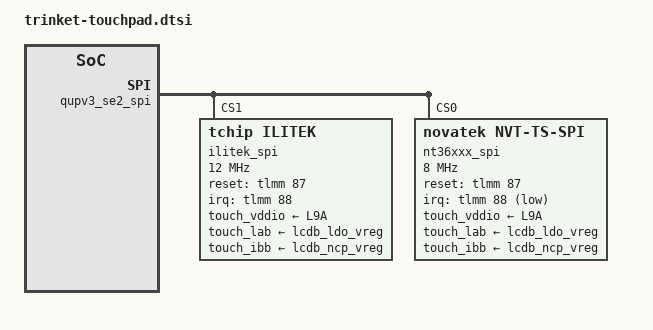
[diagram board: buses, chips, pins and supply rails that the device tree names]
/*
 * Copyright (C) 2010 - 2018 Novatek, Inc.
 *
 * $Revision$
 * $Date$
 *
 * This program is free software; you can redistribute it and/or modify
 * it under the terms of the GNU General Public License as published by
 * the Free Software Foundation; either version 2 of the License, or
 * (at your option) any later version.
 *
 * This program is distributed in the hope that it will be useful, but WITHOUT
 * ANY WARRANTY; without even the implied warranty of MERCHANTABILITY or
 * FITNESS FOR A PARTICULAR PURPOSE.  See the GNU General Public License for
 * more details.
 *
 */

&qupv3_se2_spi {

	status = "ok";
	ilitek_spi{
		status = "ok";
		compatible = "tchip,ilitek";
		reg = <1>; //change it in driver for multi spi touchscreen

		poll_mode = <0>;
		spi-max-frequency = <12000000>;

		/* regulator Configuration */
		touch_vddio-supply = <&L9A>;
		touch_lab-supply = <&lcdb_ldo_vreg>;
		touch_ibb-supply = <&lcdb_ncp_vreg>;

		touch,reset-gpio = <&tlmm 87 0x00>;
		touch,irq-gpio = <&tlmm 88 0x2002>;
	};

	nt36xxx_spi{
		status = "ok";
		compatible = "novatek,NVT-ts-spi";
		reg = <0>; //Same as CS ID

		/* SPI Configuration */
		spi-cs-high;
		spi-max-frequency = <8000000>;	//4800000,5000000,8000000,9600000,15000000,19200000

		/* regulator Configuration */
		touch_vddio-supply = <&L9A>;
		touch_lab-supply = <&lcdb_ldo_vreg>;
		touch_ibb-supply = <&lcdb_ncp_vreg>;

		/* Novatek GPIO Configuration */
		novatek,reset-gpio = <&tlmm 87 0x00>;
		novatek,irq-gpio = <&tlmm 88 0x2001>;

		/* 525 */
		//novatek,swrst-n8-addr = <0x01F01A>;

		/* 672A, 525B, 675, 526 */
		novatek,swrst-n8-addr = <0x03F0FE>;
		novatek,spi-rd-fast-addr = <0x03F310>;

		/* MP */
		novatek,mp-support-dt;

		novatek-mp-criteria-5108@0 {
			#address-cells = <1>;
			#size-cells = <0>;
			compatible = "novatek-mp-criteria-5108";

			/* MP Config */
			IC_X_CFG_SIZE = <15>;
			IC_Y_CFG_SIZE = <35>;
			IC_KEY_CFG_SIZE = <4>;
			X_Channel = <15>;
			Y_Channel = <35>;
			AIN_X = <0 1 2 3 4 5 6 7 8 9 10 11 12 13 14>;
			AIN_Y = <0 1 2 3 4 5 6 7 8 9 10 11 12 13 14 15 16 17
						18 19 20 21 22 23 24 25 26 27 28 29 30 31 32 33 34>;
			/*AIN_KEY = <0 1 2 0xFF 0xFF 0xFF 0xFF 0xFF>;*/

			/* MP Criteria */
			PS_Config_Lmt_Short_Rawdata_P = <
			    14008 14008 14008 14008 14008 14008 14008 14008 14008 14008 14008 14008 14008 14008 14008
			    14008 14008 14008 14008 14008 14008 14008 14008 14008 14008 14008 14008 14008 14008 14008
			    14008 14008 14008 14008 14008 14008 14008 14008 14008 14008 14008 14008 14008 14008 14008
			    14008 14008 14008 14008 14008 14008 14008 14008 14008 14008 14008 14008 14008 14008 14008
			    14008 14008 14008 14008 14008 14008 14008 14008 14008 14008 14008 14008 14008 14008 14008
			    14008 14008 14008 14008 14008 14008 14008 14008 14008 14008 14008 14008 14008 14008 14008
			    14008 14008 14008 14008 14008 14008 14008 14008 14008 14008 14008 14008 14008 14008 14008
			    14008 14008 14008 14008 14008 14008 14008 14008 14008 14008 14008 14008 14008 14008 14008
			    14008 14008 14008 14008 14008 14008 14008 14008 14008 14008 14008 14008 14008 14008 14008
			    14008 14008 14008 14008 14008 14008 14008 14008 14008 14008 14008 14008 14008 14008 14008
			    14008 14008 14008 14008 14008 14008 14008 14008 14008 14008 14008 14008 14008 14008 14008
			    14008 14008 14008 14008 14008 14008 14008 14008 14008 14008 14008 14008 14008 14008 14008
			    14008 14008 14008 14008 14008 14008 14008 14008 14008 14008 14008 14008 14008 14008 14008
			    14008 14008 14008 14008 14008 14008 14008 14008 14008 14008 14008 14008 14008 14008 14008
			    14008 14008 14008 14008 14008 14008 14008 14008 14008 14008 14008 14008 14008 14008 14008
			    14008 14008 14008 14008 14008 14008 14008 14008 14008 14008 14008 14008 14008 14008 14008
			    14008 14008 14008 14008 14008 14008 14008 14008 14008 14008 14008 14008 14008 14008 14008
			    14008 14008 14008 14008 14008 14008 14008 14008 14008 14008 14008 14008 14008 14008 14008
			    14008 14008 14008 14008 14008 14008 14008 14008 14008 14008 14008 14008 14008 14008 14008
			    14008 14008 14008 14008 14008 14008 14008 14008 14008 14008 14008 14008 14008 14008 14008
			    14008 14008 14008 14008 14008 14008 14008 14008 14008 14008 14008 14008 14008 14008 14008
			    14008 14008 14008 14008 14008 14008 14008 14008 14008 14008 14008 14008 14008 14008 14008
			    14008 14008 14008 14008 14008 14008 14008 14008 14008 14008 14008 14008 14008 14008 14008
			    14008 14008 14008 14008 14008 14008 14008 14008 14008 14008 14008 14008 14008 14008 14008
			    14008 14008 14008 14008 14008 14008 14008 14008 14008 14008 14008 14008 14008 14008 14008
			    14008 14008 14008 14008 14008 14008 14008 14008 14008 14008 14008 14008 14008 14008 14008
			    14008 14008 14008 14008 14008 14008 14008 14008 14008 14008 14008 14008 14008 14008 14008
			    14008 14008 14008 14008 14008 14008 14008 14008 14008 14008 14008 14008 14008 14008 14008
			    14008 14008 14008 14008 14008 14008 14008 14008 14008 14008 14008 14008 14008 14008 14008
			    14008 14008 14008 14008 14008 14008 14008 14008 14008 14008 14008 14008 14008 14008 14008
			    14008 14008 14008 14008 14008 14008 14008 14008 14008 14008 14008 14008 14008 14008 14008
			    14008 14008 14008 14008 14008 14008 14008 14008 14008 14008 14008 14008 14008 14008 14008
			    14008 14008 14008 14008 14008 14008 14008 14008 14008 14008 14008 14008 14008 14008 14008
			    14008 14008 14008 14008 14008 14008 14008 14008 14008 14008 14008 14008 14008 14008 14008
			    14008 14008 14008 14008 14008 14008 14008 14008 14008 14008 14008 14008 14008 14008 14008
			    >;

			   PS_Config_Lmt_Short_Rawdata_N = <
			    10100 10100 10100 10100 10100 10100 10100 10100 10100 10100 10100 10100 10100 10100 10100
			    10100 10100 10100 10100 10100 10100 10100 10100 10100 10100 10100 10100 10100 10100 10100
			    10100 10100 10100 10100 10100 10100 10100 10100 10100 10100 10100 10100 10100 10100 10100
			    10100 10100 10100 10100 10100 10100 10100 10100 10100 10100 10100 10100 10100 10100 10100
			    10100 10100 10100 10100 10100 10100 10100 10100 10100 10100 10100 10100 10100 10100 10100
			    10100 10100 10100 10100 10100 10100 10100 10100 10100 10100 10100 10100 10100 10100 10100
			    10100 10100 10100 10100 10100 10100 10100 10100 10100 10100 10100 10100 10100 10100 10100
			    10100 10100 10100 10100 10100 10100 10100 10100 10100 10100 10100 10100 10100 10100 10100
			    10100 10100 10100 10100 10100 10100 10100 10100 10100 10100 10100 10100 10100 10100 10100
			    10100 10100 10100 10100 10100 10100 10100 10100 10100 10100 10100 10100 10100 10100 10100
			    10100 10100 10100 10100 10100 10100 10100 10100 10100 10100 10100 10100 10100 10100 10100
			    10100 10100 10100 10100 10100 10100 10100 10100 10100 10100 10100 10100 10100 10100 10100
			    10100 10100 10100 10100 10100 10100 10100 10100 10100 10100 10100 10100 10100 10100 10100
			    10100 10100 10100 10100 10100 10100 10100 10100 10100 10100 10100 10100 10100 10100 10100
			    10100 10100 10100 10100 10100 10100 10100 10100 10100 10100 10100 10100 10100 10100 10100
			    10100 10100 10100 10100 10100 10100 10100 10100 10100 10100 10100 10100 10100 10100 10100
			    10100 10100 10100 10100 10100 10100 10100 10100 10100 10100 10100 10100 10100 10100 10100
			    10100 10100 10100 10100 10100 10100 10100 10100 10100 10100 10100 10100 10100 10100 10100
			    10100 10100 10100 10100 10100 10100 10100 10100 10100 10100 10100 10100 10100 10100 10100
			    10100 10100 10100 10100 10100 10100 10100 10100 10100 10100 10100 10100 10100 10100 10100
			    10100 10100 10100 10100 10100 10100 10100 10100 10100 10100 10100 10100 10100 10100 10100
			    10100 10100 10100 10100 10100 10100 10100 10100 10100 10100 10100 10100 10100 10100 10100
			    10100 10100 10100 10100 10100 10100 10100 10100 10100 10100 10100 10100 10100 10100 10100
			    10100 10100 10100 10100 10100 10100 10100 10100 10100 10100 10100 10100 10100 10100 10100
			    10100 10100 10100 10100 10100 10100 10100 10100 10100 10100 10100 10100 10100 10100 10100
			    10100 10100 10100 10100 10100 10100 10100 10100 10100 10100 10100 10100 10100 10100 10100
			    10100 10100 10100 10100 10100 10100 10100 10100 10100 10100 10100 10100 10100 10100 10100
			    10100 10100 10100 10100 10100 10100 10100 10100 10100 10100 10100 10100 10100 10100 10100
			    10100 10100 10100 10100 10100 10100 10100 10100 10100 10100 10100 10100 10100 10100 10100
			    10100 10100 10100 10100 10100 10100 10100 10100 10100 10100 10100 10100 10100 10100 10100
			    10100 10100 10100 10100 10100 10100 10100 10100 10100 10100 10100 10100 10100 10100 10100
			    10100 10100 10100 10100 10100 10100 10100 10100 10100 10100 10100 10100 10100 10100 10100
			    10100 10100 10100 10100 10100 10100 10100 10100 10100 10100 10100 10100 10100 10100 10100
			    10100 10100 10100 10100 10100 10100 10100 10100 10100 10100 10100 10100 10100 10100 10100
			    10100 10100 10100 10100 10100 10100 10100 10100 10100 10100 10100 10100 10100 10100 10100
			    >;

			   PS_Config_Lmt_Open_Rawdata_P = <
			    2052 2185 2263 2352 2391 2505 65535 65535 2594 2446 2414 2335 2249 2167 65535
			    2103 2200 2263 2342 2352 2344 2283 2574 2437 2442 2423 2388 2316 2236 2433
			    2118 2216 2272 2347 2355 2331 2316 2557 2401 2388 2374 2351 2288 2221 2413
			    2188 2280 2345 2414 2427 2414 2400 2607 2475 2460 2445 2424 2358 2288 2478
			    2233 2325 2386 2456 2460 2452 2436 2651 2515 2507 2501 2485 2423 2351 2518
			    2253 2335 2394 2462 2458 2453 2446 2628 2495 2486 2481 2473 2409 2332 2492
			    2043 2141 2197 2282 2340 2327 2319 2623 2394 2376 2357 2283 2208 2149 2380
			    2077 2183 2236 2327 2378 2367 2355 2659 2450 2426 2410 2332 2268 2200 2420
			    2095 2185 2236 2324 2364 2354 2337 2681 2471 2446 2433 2358 2291 2216 2423
			    2171 2273 2334 2423 2462 2456 2433 2740 2545 2518 2504 2427 2364 2288 2496
			    2224 2324 2378 2465 2495 2491 2473 2717 2545 2522 2512 2450 2381 2309 2492
			    2193 2288 2340 2420 2440 2430 2407 2700 2524 2502 2489 2439 2374 2304 2466
			    2772 2868 2928 2916 2913 2908 2905 2796 3015 3008 2998 2999 3013 2952 3060
			    2885 2977 3035 3022 3013 2999 2989 2792 3104 3097 3090 3090 3104 3047 3142
			    2851 2936 2979 2964 2957 2962 2946 2800 3074 3064 3052 3060 3081 3032 3124
			    2944 3041 3088 3070 3070 3077 3062 2875 3204 3196 3189 3182 3196 3147 3238
			    2996 3085 3129 3108 3108 3121 3108 2944 3258 3250 3242 3248 3260 3229 3306
			    2872 2952 2988 2959 2963 2969 2969 2831 3221 3232 3221 3229 3245 3218 3278
			    3042 3119 3155 3127 3127 3130 3132 2967 3329 3332 3330 3333 3348 3333 3407
			    3149 3237 3261 3229 3232 3240 3232 3057 3396 3398 3396 3395 3409 3405 3460
			    3119 3196 3209 3182 3192 3208 3208 3067 3323 3333 3337 3337 3358 3363 3424
			    3214 3288 3306 3280 3288 3309 3310 3180 3427 3431 3445 3438 3450 3460 3515
			    3368 3435 3435 3411 3414 3435 3435 3216 3528 3539 3542 3546 3562 3572 3628
			    3324 3378 3385 3360 3373 3392 3396 3202 3496 3503 3509 3522 3530 3546 3594
			    3430 3477 3481 3453 3466 3476 3487 3255 3610 3621 3624 3641 3647 3667 3731
			    3434 3467 3481 3448 3456 3461 3463 3350 3631 3640 3653 3664 3670 3696 3768
			    3542 3558 3561 3538 3538 3549 3546 3316 3648 3663 3664 3676 3684 3705 3774
			    3623 3633 3637 3612 3617 3633 3644 3417 3782 3797 3800 3810 3817 3837 3919
			    3738 3742 3732 3705 3705 3718 3718 3536 3831 3852 3853 3867 3873 3889 3984
			    3039 3119 3185 3235 3222 3222 3198 3520 3360 3356 3352 3346 3290 3206 3291
			    3120 3208 3280 3330 3314 3320 3314 3548 3402 3394 3389 3386 3343 3263 3333
			    2846 3096 3146 3198 3178 3173 3160 3445 3294 3290 3290 3296 3267 3206 3084
			    2970 3235 3283 3317 3290 3293 3286 3568 3421 3425 3415 3427 3396 3326 3198
			    3044 3378 3434 3463 3443 3450 3443 3699 3558 3564 3565 3568 3542 3473 3268
			    3034 3391 3467 3483 3464 3463 3463 3725 3585 3585 3574 3584 3571 3490 3204
			    >;

			   PS_Config_Lmt_Open_Rawdata_N = <
			    798 850 880 915 930 974 (-65535) (-65535) 1009 951 939 908 874 842 (-65535)
			    818 855 880 911 915 911 888 1001 948 949 942 929 901 869 946
			    823 861 883 912 916 906 901 994 934 929 923 914 889 864 938
			    851 887 912 939 944 939 933 1014 962 957 950 943 917 889 963
			    868 904 927 955 957 953 947 1030 978 974 972 966 942 914 979
			    876 908 931 957 955 954 951 1022 970 967 964 962 936 907 969
			    794 832 854 887 910 904 902 1020 931 924 916 888 859 836 925
			    808 848 869 904 925 920 916 1034 953 943 937 907 882 855 941
			    814 850 869 903 919 915 908 1042 960 951 946 917 890 861 942
			    844 884 907 942 957 955 946 1065 990 979 973 944 919 889 971
			    865 903 925 958 970 968 962 1056 990 981 977 953 926 898 969
			    852 889 910 941 949 945 936 1050 981 973 968 948 923 896 959
			    1078 1115 1139 1134 1132 1131 1130 1087 1172 1169 1165 1166 1172 1148 1190
			    1122 1158 1180 1175 1172 1166 1162 1085 1207 1204 1201 1201 1207 1184 1221
			    1108 1141 1158 1153 1150 1151 1145 1089 1195 1191 1187 1190 1198 1179 1215
			    1145 1182 1201 1193 1193 1196 1191 1118 1246 1243 1240 1237 1243 1224 1259
			    1165 1200 1216 1209 1209 1214 1209 1145 1267 1263 1261 1263 1267 1256 1285
			    1117 1148 1162 1150 1152 1154 1154 1100 1252 1257 1252 1256 1262 1251 1275
			    1183 1212 1226 1216 1216 1217 1218 1154 1294 1295 1295 1296 1302 1296 1324
			    1224 1258 1268 1256 1257 1260 1257 1188 1321 1321 1321 1320 1326 1324 1345
			    1212 1243 1248 1237 1241 1247 1247 1192 1292 1296 1298 1298 1305 1308 1331
			    1249 1279 1285 1275 1279 1286 1287 1237 1332 1334 1340 1337 1341 1345 1366
			    1309 1336 1336 1326 1327 1336 1336 1251 1372 1376 1377 1379 1385 1389 1411
			    1293 1313 1316 1307 1312 1319 1321 1245 1359 1362 1364 1369 1373 1379 1397
			    1333 1352 1354 1342 1347 1351 1356 1266 1403 1408 1409 1416 1418 1426 1450
			    1335 1348 1354 1341 1344 1346 1346 1303 1412 1415 1420 1425 1427 1437 1465
			    1377 1383 1384 1375 1375 1380 1379 1289 1419 1424 1425 1429 1433 1440 1467
			    1408 1412 1414 1405 1406 1412 1417 1328 1471 1476 1477 1481 1484 1492 1524
			    1453 1455 1451 1440 1440 1445 1445 1375 1490 1498 1498 1504 1506 1512 1549
			    1182 1212 1238 1258 1253 1253 1243 1369 1307 1305 1303 1301 1279 1247 1280
			    1213 1247 1275 1295 1289 1291 1289 1379 1323 1319 1318 1317 1300 1268 1296
			    1107 1204 1223 1243 1235 1234 1229 1340 1281 1279 1279 1281 1270 1247 1199
			    1155 1258 1276 1290 1279 1280 1277 1387 1330 1332 1328 1332 1321 1293 1243
			    1183 1313 1335 1346 1338 1341 1338 1438 1383 1386 1386 1387 1377 1350 1271
			    1179 1318 1348 1354 1347 1346 1346 1448 1394 1394 1389 1393 1388 1357 1246
			    >;

			   PS_Config_Lmt_FW_Rawdata_P = <
			    1097 1117 1134 1138 1155 1143 65535 65535 1103 1136 1124 1104 1136 1111 65535
			    1134 1142 1110 1103 1129 1129 1108 1118 1153 1138 1129 1115 1131 1114 1118
			    1110 1107 1146 1129 1143 1108 1120 1125 1125 1115 1115 1138 1127 1107 1146
			    1131 1110 1155 1094 1104 1125 1149 1141 1124 1108 1125 1149 1141 1125 1138
			    1101 1097 1107 1110 1150 1163 1086 1096 1139 1142 1134 1089 1132 1129 1121
			    1131 1138 1166 1097 1120 1141 1113 1145 1117 1121 1145 1118 1139 1136 1139
			    1072 1097 1117 1155 1127 1118 1129 1141 1108 1120 1141 1141 1134 1124 1129
			    1099 1125 1079 1155 1079 1110 1163 1142 1085 1118 1164 1153 1125 1110 1164
			    1076 1163 1100 1127 1132 1090 1121 1159 1094 1129 1125 1114 1139 1113 1113
			    1108 1100 1149 1099 1118 1145 1131 1107 1152 1132 1093 1090 1160 1149 1125
			    1118 1118 1148 1082 1153 1152 1110 1124 1117 1113 1129 1120 1115 1121 1093
			    1111 1114 1132 1139 1120 1125 1108 1120 1104 1138 1092 1125 1148 1125 1153
			    1114 1096 1131 1157 1111 1106 1121 1138 1145 1177 1096 1065 1104 1089 1127
			    1114 1106 1121 1139 1134 1117 1110 1173 1111 1117 1125 1118 1128 1114 1090
			    1134 1148 1101 1076 1117 1157 1176 1121 1124 1146 1134 1082 1104 1086 1115
			    1086 1122 1110 1127 1138 1124 1087 1136 1090 1120 1135 1159 1169 1157 1086
			    1097 1135 1092 1128 1157 1115 1083 1111 1132 1136 1118 1110 1099 1093 1103
			    1082 1142 1100 1106 1127 1148 1106 1125 1142 1155 1169 1082 1082 1079 1093
			    1087 1120 1083 1120 1153 1111 1092 1124 1124 1087 1097 1107 1136 1149 1174
			    1132 1075 1103 1141 1145 1111 1103 1131 1076 1104 1114 1128 1135 1103 1131
			    1128 1075 1097 1135 1162 1125 1090 1111 1113 1143 1160 1162 1104 1075 1086
			    1120 1117 1094 1142 1134 1120 1145 1122 1099 1107 1111 1121 1142 1122 1150
			    1107 1150 1094 1113 1146 1110 1117 1135 1115 1122 1100 1124 1124 1150 1169
			    1101 1111 1121 1087 1113 1128 1127 1121 1115 1118 1135 1132 1145 1099 1132
			    1108 1153 1115 1103 1122 1139 1149 1155 1125 1087 1082 1113 1143 1122 1124
			    1148 1093 1125 1171 1174 1064 1065 1096 1101 1113 1120 1152 1157 1107 1111
			    1076 1138 1155 1155 1065 1080 1108 1127 1188 1073 1061 1086 1101 1120 1176
			    1117 1120 1138 1099 1120 1145 1124 1097 1143 1157 1089 1078 1085 1101 1072
			    1089 1096 1124 1174 1150 1107 1090 1180 1148 1145 1152 1139 1118 1080 1110
			    1120 1111 1141 1111 1141 1146 1104 1104 1162 1148 1120 1103 1159 1090 1107
			    1086 1115 1127 1113 1120 1141 1114 1138 1061 1057 1061 1068 1185 1136 1136
			    1110 1100 1148 1114 1111 1120 1124 1118 1113 1106 1128 1131 1121 1110 1134
			    1107 1143 1087 1120 1132 1166 1171 1148 1079 1085 1072 1097 1076 1177 1078
			    1160 1096 1166 1065 1107 1132 1143 1128 1104 1118 1096 1101 1090 1152 1136
			    1092 1160 1114 1120 1163 1100 1089 1110 1115 1108 1120 1120 1114 1124 1131
			    >;

			   PS_Config_Lmt_FW_Rawdata_N = <
			    470 478 486 487 495 490 (-65535) (-65535) 472 487 481 473 487 476 (-65535)
			    486 489 475 472 484 484 475 479 494 487 484 478 484 477 479
			    475 474 491 484 490 475 480 482 482 478 478 487 483 474 491
			    484 475 495 469 473 482 492 489 481 475 482 492 489 482 487
			    472 470 474 475 493 498 465 469 488 489 486 466 485 484 480
			    484 487 499 470 480 489 477 490 478 480 490 479 488 487 488
			    459 470 478 495 483 479 484 489 475 480 489 489 486 481 484
			    471 482 462 495 462 475 498 489 465 479 499 494 482 475 499
			    461 498 471 483 485 467 480 496 469 484 482 477 488 477 477
			    475 471 492 471 479 490 484 474 493 485 468 467 497 492 482
			    479 479 492 463 494 493 475 481 478 477 484 480 478 480 468
			    476 477 485 488 480 482 475 480 473 487 468 482 492 482 494
			    477 469 484 496 476 474 480 487 490 504 469 456 473 466 483
			    477 474 480 488 486 478 475 502 476 478 482 479 483 477 467
			    486 492 472 461 478 496 504 480 481 491 486 463 473 465 478
			    465 481 475 483 487 481 466 487 467 480 486 496 501 496 465
			    470 486 468 483 496 478 464 476 485 487 479 475 471 468 472
			    463 489 471 474 483 492 474 482 489 495 501 463 463 462 468
			    466 480 464 480 494 476 468 481 481 466 470 474 487 492 503
			    485 460 472 489 490 476 472 484 461 473 477 483 486 472 484
			    483 460 470 486 498 482 467 476 477 490 497 498 473 460 465
			    480 478 469 489 486 480 490 481 471 474 476 480 489 481 493
			    474 493 469 477 491 475 478 486 478 481 471 481 481 493 501
			    472 476 480 466 477 483 483 480 478 479 486 485 490 471 485
			    475 494 478 472 481 488 492 495 482 466 463 477 490 481 481
			    492 468 482 502 503 456 456 469 472 477 480 493 496 474 476
			    461 487 495 495 456 463 475 483 509 460 454 465 472 480 504
			    478 480 487 471 480 490 481 470 490 496 466 462 465 472 459
			    466 469 481 503 493 474 467 505 492 490 493 488 479 463 475
			    480 476 489 476 489 491 473 473 498 492 480 472 496 467 474
			    465 478 483 477 480 489 477 487 454 453 454 457 508 487 487
			    475 471 492 477 476 480 481 479 477 474 483 484 480 475 486
			    474 490 466 480 485 499 502 492 462 465 459 470 461 504 462
			    497 469 499 456 474 485 490 483 473 479 469 472 467 493 487
			    468 497 477 480 498 471 466 475 478 475 480 480 477 481 484
			    >;

			   PS_Config_Lmt_FW_CC_P = <
			    42 44 45 45 46 46 65535 65535 42 44 44 44 44 42 65535
			    41 41 42 42 44 44 44 40 44 44 44 44 44 44 44
			    42 42 44 45 45 45 45 40 42 42 44 44 44 44 44
			    44 44 45 45 45 46 46 40 42 44 44 44 44 44 44
			    42 42 44 44 44 45 45 40 42 44 44 44 44 44 44
			    44 44 44 45 45 45 46 40 42 44 44 44 44 44 44
			    42 42 44 44 45 45 45 41 44 44 45 45 44 44 45
			    44 44 44 45 45 46 46 41 45 45 45 45 45 45 45
			    42 42 42 44 44 45 45 41 44 44 45 45 44 44 45
			    42 44 44 45 45 45 46 41 44 44 44 44 44 44 44
			    42 42 44 44 45 45 45 41 44 44 44 44 44 44 44
			    42 42 44 45 45 45 45 41 45 45 45 45 45 45 45
			    48 48 48 49 49 49 49 49 45 45 46 46 46 46 46
			    49 49 49 49 49 51 51 49 46 46 48 48 48 48 48
			    49 48 49 49 49 49 51 48 46 46 46 46 46 46 48
			    49 49 49 49 51 51 51 49 46 46 46 46 48 48 48
			    49 49 49 49 49 51 51 48 46 46 46 48 48 48 48
			    51 49 49 51 51 51 51 48 48 48 48 49 49 49 49
			    49 48 49 49 49 49 51 48 46 46 46 48 48 48 48
			    51 49 51 51 51 51 52 48 48 48 48 48 48 49 49
			    49 49 49 49 49 49 51 49 46 46 48 48 48 48 48
			    49 49 49 49 49 51 51 49 48 48 48 48 48 49 49
			    49 49 49 49 49 51 51 48 46 46 48 48 48 48 48
			    52 51 52 52 52 52 52 49 48 48 48 48 48 49 49
			    51 49 51 51 51 51 51 49 48 48 48 48 48 49 49
			    52 51 51 51 51 52 52 51 48 48 48 48 48 49 49
			    52 51 51 51 52 52 52 49 48 49 49 49 49 49 49
			    52 51 51 51 51 51 52 51 48 48 49 49 49 49 51
			    51 51 51 51 51 51 51 49 48 48 48 48 48 48 49
			    45 45 45 46 46 46 48 44 46 46 46 46 45 45 45
			    46 46 46 48 48 48 48 45 48 48 48 48 46 46 46
			    46 46 46 48 48 48 48 45 48 48 48 48 46 46 46
			    48 46 48 48 48 48 48 45 48 48 48 48 48 46 48
			    46 46 46 48 48 48 48 45 46 46 48 48 48 46 48
			    49 46 48 48 48 49 49 46 48 48 48 48 48 48 49
			    >;

			   PS_Config_Lmt_FW_CC_N = <
			    19 19 20 20 21 21 (-65535) (-65535) 19 19 19 19 19 19 (-65535)
			    18 18 19 19 19 19 19 17 19 19 19 19 19 19 19
			    19 19 19 20 20 20 20 17 19 19 19 19 19 19 19
			    19 19 20 20 20 21 21 17 19 19 19 19 19 19 19
			    19 19 19 19 19 20 20 17 19 19 19 19 19 19 19
			    19 19 19 20 20 20 21 17 19 19 19 19 19 19 19
			    19 19 19 19 20 20 20 18 19 19 20 20 19 19 20
			    19 19 19 20 20 21 21 18 20 20 20 20 20 20 20
			    19 19 19 19 19 20 20 18 19 19 20 20 19 19 20
			    19 19 19 20 20 20 21 18 19 19 19 19 19 19 19
			    19 19 19 19 20 20 20 18 19 19 19 19 19 19 19
			    19 19 19 20 20 20 20 18 20 20 20 20 20 20 20
			    21 21 21 22 22 22 22 22 20 20 21 21 21 21 21
			    22 22 22 22 22 22 22 22 21 21 21 21 21 21 21
			    22 21 22 22 22 22 22 21 21 21 21 21 21 21 21
			    22 22 22 22 22 22 22 22 21 21 21 21 21 21 21
			    22 22 22 22 22 22 22 21 21 21 21 21 21 21 21
			    22 22 22 22 22 22 22 21 21 21 21 22 22 22 22
			    22 21 22 22 22 22 22 21 21 21 21 21 21 21 21
			    22 22 22 22 22 22 23 21 21 21 21 21 21 22 22
			    22 22 22 22 22 22 22 22 21 21 21 21 21 21 21
			    22 22 22 22 22 22 22 22 21 21 21 21 21 22 22
			    22 22 22 22 22 22 22 21 21 21 21 21 21 21 21
			    23 22 23 23 23 23 23 22 21 21 21 21 21 22 22
			    22 22 22 22 22 22 22 22 21 21 21 21 21 22 22
			    23 22 22 22 22 23 23 22 21 21 21 21 21 22 22
			    23 22 22 22 23 23 23 22 21 22 22 22 22 22 22
			    23 22 22 22 22 22 23 22 21 21 22 22 22 22 22
			    22 22 22 22 22 22 22 22 21 21 21 21 21 21 22
			    20 20 20 21 21 21 21 19 21 21 21 21 20 20 20
			    21 21 21 21 21 21 21 20 21 21 21 21 21 21 21
			    21 21 21 21 21 21 21 20 21 21 21 21 21 21 21
			    21 21 21 21 21 21 21 20 21 21 21 21 21 21 21
			    21 21 21 21 21 21 21 20 21 21 21 21 21 21 21
			    22 21 21 21 21 22 22 21 21 21 21 21 21 21 22
			    >;

			   PS_Config_Lmt_FW_Diff_P = <
			    50 50 50 50 50 50 65535 65535 50 50 50 50 50 50 65535
			    50 50 50 50 50 50 50 50 50 50 50 50 50 50 50
			    50 50 50 50 50 50 50 50 50 50 50 50 50 50 50
			    50 50 50 50 50 50 50 50 50 50 50 50 50 50 50
			    50 50 50 50 50 50 50 50 50 50 50 50 50 50 50
			    50 50 50 50 50 50 50 50 50 50 50 50 50 50 50
			    50 50 50 50 50 50 50 50 50 50 50 50 50 50 50
			    50 50 50 50 50 50 50 50 50 50 50 50 50 50 50
			    50 50 50 50 50 50 50 50 50 50 50 50 50 50 50
			    50 50 50 50 50 50 50 50 50 50 50 50 50 50 50
			    50 50 50 50 50 50 50 50 50 50 50 50 50 50 50
			    50 50 50 50 50 50 50 50 50 50 50 50 50 50 50
			    50 50 50 50 50 50 50 50 50 50 50 50 50 50 50
			    50 50 50 50 50 50 50 50 50 50 50 50 50 50 50
			    50 50 50 50 50 50 50 50 50 50 50 50 50 50 50
			    50 50 50 50 50 50 50 50 50 50 50 50 50 50 50
			    50 50 50 50 50 50 50 50 50 50 50 50 50 50 50
			    50 50 50 50 50 50 50 50 50 50 50 50 50 50 50
			    50 50 50 50 50 50 50 50 50 50 50 50 50 50 50
			    50 50 50 50 50 50 50 50 50 50 50 50 50 50 50
			    50 50 50 50 50 50 50 50 50 50 50 50 50 50 50
			    50 50 50 50 50 50 50 50 50 50 50 50 50 50 50
			    50 50 50 50 50 50 50 50 50 50 50 50 50 50 50
			    50 50 50 50 50 50 50 50 50 50 50 50 50 50 50
			    50 50 50 50 50 50 50 50 50 50 50 50 50 50 50
			    50 50 50 50 50 50 50 50 50 50 50 50 50 50 50
			    50 50 50 50 50 50 50 50 50 50 50 50 50 50 50
			    50 50 50 50 50 50 50 50 50 50 50 50 50 50 50
			    50 50 50 50 50 50 50 50 50 50 50 50 50 50 50
			    50 50 50 50 50 50 50 50 50 50 50 50 50 50 50
			    50 50 50 50 50 50 50 50 50 50 50 50 50 50 50
			    50 50 50 50 50 50 50 50 50 50 50 50 50 50 50
			    50 50 50 50 50 50 50 50 50 50 50 50 50 50 50
			    50 50 50 50 50 50 50 50 50 50 50 50 50 50 50
			    50 50 50 50 50 50 50 50 50 50 50 50 50 50 50
			    >;

			   PS_Config_Lmt_FW_Diff_N = <
			    (-50) (-50) (-50) (-50) (-50) (-50) (-65535) (-65535) (-50) (-50) (-50) (-50) (-50) (-50) (-65535)
			    (-50) (-50) (-50) (-50) (-50) (-50) (-50) (-50) (-50) (-50) (-50) (-50) (-50) (-50) (-50)
			    (-50) (-50) (-50) (-50) (-50) (-50) (-50) (-50) (-50) (-50) (-50) (-50) (-50) (-50) (-50)
			    (-50) (-50) (-50) (-50) (-50) (-50) (-50) (-50) (-50) (-50) (-50) (-50) (-50) (-50) (-50)
			    (-50) (-50) (-50) (-50) (-50) (-50) (-50) (-50) (-50) (-50) (-50) (-50) (-50) (-50) (-50)
			    (-50) (-50) (-50) (-50) (-50) (-50) (-50) (-50) (-50) (-50) (-50) (-50) (-50) (-50) (-50)
			    (-50) (-50) (-50) (-50) (-50) (-50) (-50) (-50) (-50) (-50) (-50) (-50) (-50) (-50) (-50)
			    (-50) (-50) (-50) (-50) (-50) (-50) (-50) (-50) (-50) (-50) (-50) (-50) (-50) (-50) (-50)
			    (-50) (-50) (-50) (-50) (-50) (-50) (-50) (-50) (-50) (-50) (-50) (-50) (-50) (-50) (-50)
			    (-50) (-50) (-50) (-50) (-50) (-50) (-50) (-50) (-50) (-50) (-50) (-50) (-50) (-50) (-50)
			    (-50) (-50) (-50) (-50) (-50) (-50) (-50) (-50) (-50) (-50) (-50) (-50) (-50) (-50) (-50)
			    (-50) (-50) (-50) (-50) (-50) (-50) (-50) (-50) (-50) (-50) (-50) (-50) (-50) (-50) (-50)
			    (-50) (-50) (-50) (-50) (-50) (-50) (-50) (-50) (-50) (-50) (-50) (-50) (-50) (-50) (-50)
			    (-50) (-50) (-50) (-50) (-50) (-50) (-50) (-50) (-50) (-50) (-50) (-50) (-50) (-50) (-50)
			    (-50) (-50) (-50) (-50) (-50) (-50) (-50) (-50) (-50) (-50) (-50) (-50) (-50) (-50) (-50)
			    (-50) (-50) (-50) (-50) (-50) (-50) (-50) (-50) (-50) (-50) (-50) (-50) (-50) (-50) (-50)
			    (-50) (-50) (-50) (-50) (-50) (-50) (-50) (-50) (-50) (-50) (-50) (-50) (-50) (-50) (-50)
			    (-50) (-50) (-50) (-50) (-50) (-50) (-50) (-50) (-50) (-50) (-50) (-50) (-50) (-50) (-50)
			    (-50) (-50) (-50) (-50) (-50) (-50) (-50) (-50) (-50) (-50) (-50) (-50) (-50) (-50) (-50)
			    (-50) (-50) (-50) (-50) (-50) (-50) (-50) (-50) (-50) (-50) (-50) (-50) (-50) (-50) (-50)
			    (-50) (-50) (-50) (-50) (-50) (-50) (-50) (-50) (-50) (-50) (-50) (-50) (-50) (-50) (-50)
			    (-50) (-50) (-50) (-50) (-50) (-50) (-50) (-50) (-50) (-50) (-50) (-50) (-50) (-50) (-50)
			    (-50) (-50) (-50) (-50) (-50) (-50) (-50) (-50) (-50) (-50) (-50) (-50) (-50) (-50) (-50)
			    (-50) (-50) (-50) (-50) (-50) (-50) (-50) (-50) (-50) (-50) (-50) (-50) (-50) (-50) (-50)
			    (-50) (-50) (-50) (-50) (-50) (-50) (-50) (-50) (-50) (-50) (-50) (-50) (-50) (-50) (-50)
			    (-50) (-50) (-50) (-50) (-50) (-50) (-50) (-50) (-50) (-50) (-50) (-50) (-50) (-50) (-50)
			    (-50) (-50) (-50) (-50) (-50) (-50) (-50) (-50) (-50) (-50) (-50) (-50) (-50) (-50) (-50)
			    (-50) (-50) (-50) (-50) (-50) (-50) (-50) (-50) (-50) (-50) (-50) (-50) (-50) (-50) (-50)
			    (-50) (-50) (-50) (-50) (-50) (-50) (-50) (-50) (-50) (-50) (-50) (-50) (-50) (-50) (-50)
			    (-50) (-50) (-50) (-50) (-50) (-50) (-50) (-50) (-50) (-50) (-50) (-50) (-50) (-50) (-50)
			    (-50) (-50) (-50) (-50) (-50) (-50) (-50) (-50) (-50) (-50) (-50) (-50) (-50) (-50) (-50)
			    (-50) (-50) (-50) (-50) (-50) (-50) (-50) (-50) (-50) (-50) (-50) (-50) (-50) (-50) (-50)
			    (-50) (-50) (-50) (-50) (-50) (-50) (-50) (-50) (-50) (-50) (-50) (-50) (-50) (-50) (-50)
			    (-50) (-50) (-50) (-50) (-50) (-50) (-50) (-50) (-50) (-50) (-50) (-50) (-50) (-50) (-50)
			    (-50) (-50) (-50) (-50) (-50) (-50) (-50) (-50) (-50) (-50) (-50) (-50) (-50) (-50) (-50)
			    >;

			PS_Config_Diff_Test_Frame = <50>;
		};
	};
};
